# STM32H7P4 register map
File version: 2.0.0
CPU: CM7 r1p2, little endian, MPU, FPU, 4 interrupt priority bits
Registers are 32-bit, read-write, reset 0x0 unless marked. A register's access mark holds for its fields unless they carry their own. Offsets are from the block's base; [hi:lo] are bit positions.

## DLYBXS1 — DLYB register block
Base 0x52006000
Same registers: DLYBSD1 0x52008000
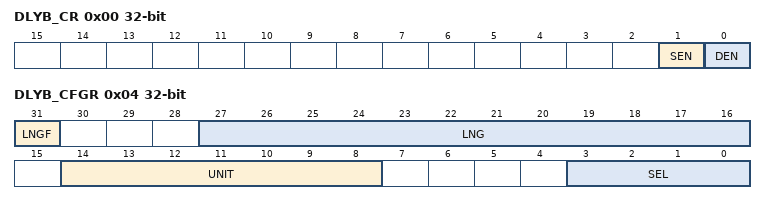
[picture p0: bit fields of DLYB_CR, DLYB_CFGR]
0x00 DLYB_CR — DLYB control register
  [1] SEN — Sampler length enable bit
    0=Sampler length and register access to UNIT[6:0] and SEL[3:0] disabled, output clock enabled; 1=Sampler length and register access to UNIT[6:0] and SEL[3:0] enabled, output clock disabled
  [0] DEN — Delay block enable bit
    0=DLYB disabled; 1=DLYB enabled
0x04 DLYB_CFGR — DLYB configuration register
  [31] LNGF ro — Length valid flag
    0=Length value in LNG is not valid; 1=Length value in LNG is valid
  [27:16] LNG ro — Delay line length value
  [14:8] UNIT — Delay of a unit delay cell.
  [3:0] SEL — Phase for the output clock.

## FMAC1 — FMAC register block
Base 0x48004800
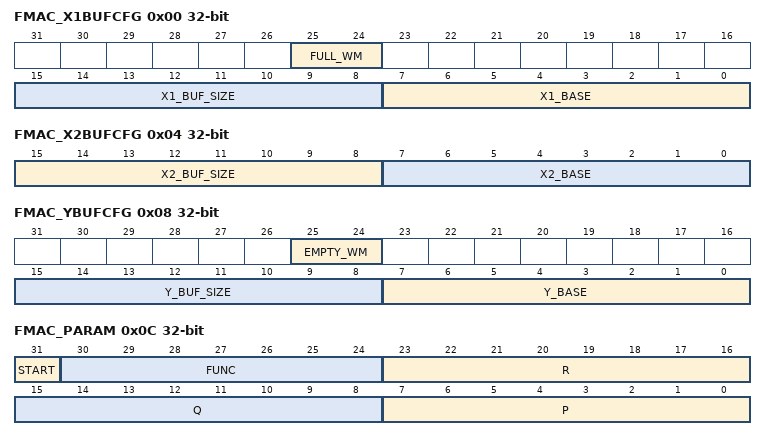
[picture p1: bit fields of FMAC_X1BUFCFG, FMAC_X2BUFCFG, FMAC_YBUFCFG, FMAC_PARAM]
0x00 FMAC_X1BUFCFG — FMAC X1 buffer configuration register
  [25:24] FULL_WM — Watermark for buffer full flag
    0=Threshold = 1; 1=Threshold = 2
  [15:8] X1_BUF_SIZE — Allocated size of X1 buffer in 16-bit words
  [7:0] X1_BASE — Base address of X1 buffer
0x04 FMAC_X2BUFCFG — FMAC X2 buffer configuration register
  [15:8] X2_BUF_SIZE — Size of X2 buffer in 16-bit words
  [7:0] X2_BASE — Base address of X2 buffer
0x08 FMAC_YBUFCFG — FMAC Y buffer configuration register
  [25:24] EMPTY_WM — Watermark for buffer empty flag
    0=Threshold = 1; 1=Threshold = 2
  [15:8] Y_BUF_SIZE — Size of Y buffer in 16-bit words
  [7:0] Y_BASE — Base address of Y buffer
0x0C FMAC_PARAM — FMAC parameter register
  [31] START — Enable execution
    0=Stop execution; 1=Start execution
  [30:24] FUNC — Function
    1=Load X1 buffer
  [23:16] R — Input parameter R.
  [15:8] Q — Input parameter Q.
  [7:0] P — Input parameter P.
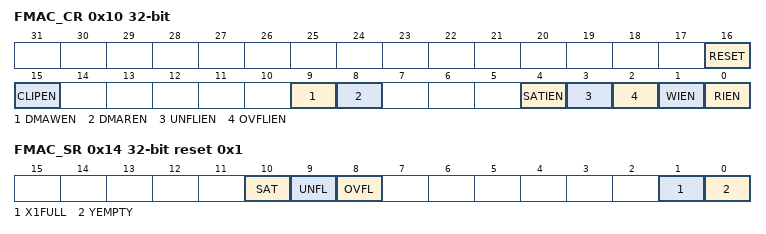
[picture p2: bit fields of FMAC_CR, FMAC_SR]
0x10 FMAC_CR — FMAC control register
  [16] RESET — Reset FMAC unit
    0=Reset inactive; 1=Reset active
  [15] CLIPEN — Enable clipping
    0=Clipping disabled; 1=Clipping enabled
  [9] DMAWEN — Enable DMA write channel requests
    0=Disable; 1=Enable
  [8] DMAREN — Enable DMA read channel requests
    0=Disable; 1=Enable
  [4] SATIEN — Enable saturation error interrupts
    0=Disabled; 1=Enabled
  [3] UNFLIEN — Enable underflow error interrupts
    0=Disabled; 1=Enabled
  [2] OVFLIEN — Enable overflow error interrupts
    0=Disabled; 1=Enabled
  [1] WIEN — Enable write interrupt
    0=Disabled; 1=Enabled
  [0] RIEN — Enable read interrupt
    0=Disabled; 1=Enabled
0x14 FMAC_SR ro reset 0x1 — FMAC status register
  [10] SAT — Saturation error flag
    0=No saturation detected; 1=Saturation detected
  [9] UNFL — Underflow error flag
    0=No underflow detected; 1=Underflow detected
  [8] OVFL — Overflow error flag
    0=No overflow detected; 1=Overflow detected
  [1] X1FULL — X1 buffer full flag
    0=X1 buffer not full; 1=X1 buffer full
  [0] YEMPTY — Y buffer empty flag
    0=Y buffer not empty; 1=Y buffer empty
0x18 FMAC_WDATA wo — FMAC write data register
  [15:0] WDATA — Write data
0x1C FMAC_RDATA ro — FMAC read data register
  [15:0] RDATA — Read data

## IWDG — IWDG register block
Base 0x58004800
0x00 IWDG_KR wo — IWDG key register
  [15:0] KEY — Key value (write only, read 0x0000)
0x04 IWDG_PR — IWDG prescaler register
  [3:0] PR — Prescaler divider
    0=divider / 4; 1=divider / 8; 2=divider / 16; 3=divider / 32; 4=divider / 64; 5=divider / 128; 6=divider / 256; 7=divider / 512
0x08 IWDG_RLR reset 0xFFF — IWDG reload register
  [11:0] RL — Watchdog counter reload value
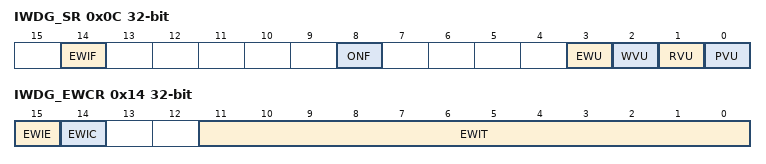
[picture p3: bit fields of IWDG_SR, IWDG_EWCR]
0x0C IWDG_SR ro — IWDG status register
  [14] EWIF — Watchdog early interrupt flag
  [8] ONF — Watchdog enable status bit
    0=The IWDG is not activated; 1=The IWDG is activated and needs to be refreshed regularly by the application
  [3] EWU — Watchdog interrupt comparator value update
  [2] WVU — Watchdog counter window value update
  [1] RVU — Watchdog counter reload value update
  [0] PVU — Watchdog prescaler value update
0x10 IWDG_WINR reset 0xFFF — IWDG window register
  [11:0] WIN — Watchdog counter window value
0x14 IWDG_EWCR — IWDG early wake-up interrupt register
  [15] EWIE — Watchdog early interrupt enable
    0=The early interrupt interface is disabled; 1=The early interrupt interface is enabled
  [14] EWIC wo — Watchdog early interrupt acknowledge
  [11:0] EWIT — Watchdog counter window value
